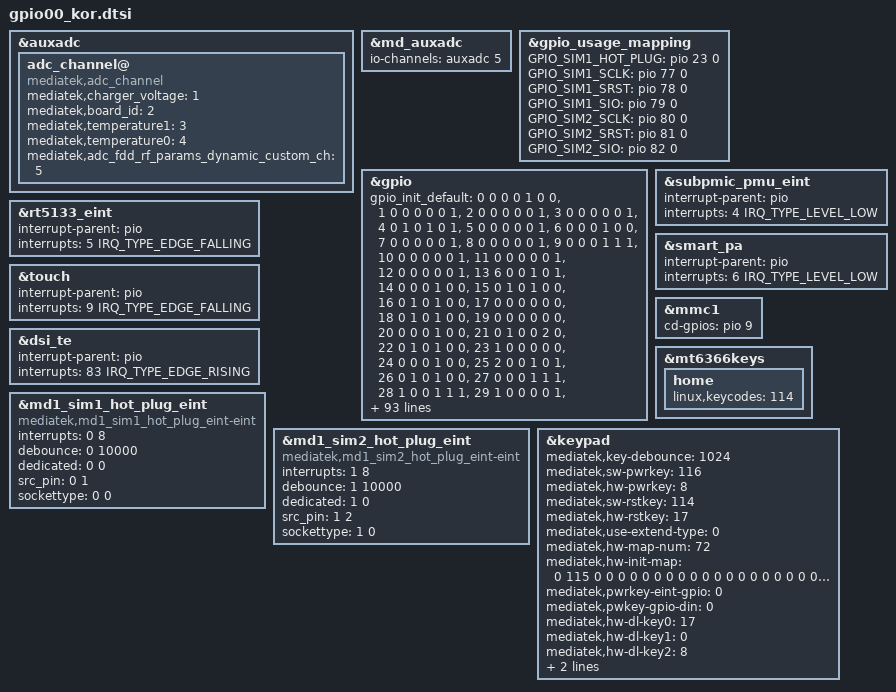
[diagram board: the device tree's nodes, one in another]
// SPDX-License-Identifier: (GPL-2.0 OR MIT)
/*
 * Copyright (C) 2022 MediaTek Inc.
 */
/*
 * Generated by MTK SP DrvGen Version: 3.5.160809 for MT6789.
 * 2022-03-30 15:44:54
 * Do Not Modify The File.
 * Copyright Mediatek Inc. (c) 2022.
 */

/*************************
 * ADC DTSI File
 *************************/
&auxadc {
	adc_channel@ {
		compatible = "mediatek,adc_channel";
		mediatek,charger_voltage = <1>;
		mediatek,board_id = <2>;
		mediatek,temperature1 = <3>;
		mediatek,temperature0 = <4>;
		mediatek,adc_fdd_rf_params_dynamic_custom_ch = <5>;
		status = "okay";
	};
};
&md_auxadc {
	io-channels = <&auxadc 5>;
};

/*************************
 * CLK_BUF DTSI File
 *************************/


#if 0
/*************************
 * I2C DTSI File
 *************************/
&pio {
	if_pmic_irq: if_pmic_irq {
		pins_cmd_dat {
			pinmux = <PINMUX_GPIO7__FUNC_GPIO7>;
			slew-rate = <1>;
			bias-disable;
			output-high;
		};
	};
	usbpd_irq: usbpd_irq {
		pins_cmd_dat {
			pinmux = <PINMUX_GPIO8__FUNC_GPIO8>;
			slew-rate = <1>;
			bias-disable;
			output-high;
		};
	};
};

&i2c0 {
	#address-cells = <1>;
	#size-cells = <0>;
	status = "okay";
	clock-frequency = <400000>;

	usbpd-sm5714@33 {
		status = "okay";
		compatible = "sm5714-usbpd";
		reg = <0x33>;
		pinctrl-names = "default";
		pinctrl-0 = <&usbpd_irq>;
		usbpd,usbpd_int = <&pio 8 0>;

		support_pd_role_swap;
		pdic-manager {
			/* sink */
			pdic,max_power = <5000>;
			pdic_op_power = <2500>;
			pdic_max_voltage = <6000>;
			pdic_max_current = <2000>;
			pdic,min_current = <500>;
			pdic,giveback = <0>;
			pdic,usb_com_capable = <1>;
			pdic,no_usb_suspend = <1>;

			/* source */
			source,max_voltage = <5000>;
			source,min_voltage = <4000>;
			source,max_power = <2500>;
		};
	};

	sm5714@49{
		status = "okay";
		compatible = "siliconmitus,sm5714mfd";
		reg = <0x49>;
		pinctrl-names = "default";
		pinctrl-0 = <&if_pmic_irq>;
		sm5714,irq-gpio = <&pio 7 0>;
		sm5714,wakeup;
	};
};
#endif

/*************************
 * GPIO DTSI File
 *************************/

&gpio_usage_mapping {
	GPIO_SIM1_HOT_PLUG = <&pio 23 0>;
	GPIO_SIM1_SCLK = <&pio 77 0>;
	GPIO_SIM1_SRST = <&pio 78 0>;
	GPIO_SIM1_SIO = <&pio 79 0>;
	GPIO_SIM2_SCLK = <&pio 80 0>;
	GPIO_SIM2_SRST = <&pio 81 0>;
	GPIO_SIM2_SIO = <&pio 82 0>;
};

&gpio{
	gpio_init_default = <0 0 0 0 1 0 0>,	/* FG_ERR */
		<1 0 0 0 0 0 1>,
		<2 0 0 0 0 0 1>,
		<3 0 0 0 0 0 1>,
		<4 0 1 0 1 0 1>,
		<5 0 0 0 0 0 1>,
		<6 0 0 0 1 0 0>,	/* OCTA_ESD_DET */
		<7 0 0 0 0 0 1>,
		<8 0 0 0 0 0 1>,
		<9 0 0 0 1 1 1>,
		<10 0 0 0 0 0 1>,
		<11 0 0 0 0 0 1>,
		<12 0 0 0 0 0 1>,
		<13 6 0 0 1 0 1>,
		<14 0 0 0 1 0 0>,	/* PCD_INT */
		<15 0 1 0 1 0 0>,
		<16 0 1 0 1 0 0>,
		<17 0 0 0 0 0 0>,
		<18 0 1 0 1 0 0>,
		<19 0 0 0 0 0 0>,
		<20 0 0 0 1 0 0>,
		<21 0 1 0 0 2 0>,	/* LCD_EN_3P0 */
		<22 0 1 0 1 0 0>,
		<23 1 0 0 0 0 0>,
		<24 0 0 0 1 0 0>,
		<25 2 0 0 1 0 1>,
		<26 0 1 0 1 0 0>,	/* RCAM3_LDO_EN */
		<27 0 0 0 1 1 1>,	/* BAT_ID_1 */
		<28 1 0 0 1 1 1>,
		<29 1 0 0 0 0 1>,
		<30 0 0 0 1 0 0>,	/* NC */
		<31 0 0 0 1 0 0>,	/* NC */
		<32 0 0 0 1 0 0>,	/* NC */
		<33 0 0 0 1 0 0>,	/* NC */
		<34 0 1 0 1 0 0>,
		<35 0 0 0 0 2 0>,	/* LCD_CON_DET */
		<36 0 0 0 0 0 0>,
		<37 0 0 0 0 0 0>,
		<38 2 0 0 0 0 1>,
		<39 2 0 0 0 0 1>,
		<40 2 0 0 0 0 1>,
		<41 2 0 0 1 0 1>,
		<42 0 1 0 0 0 0>,
		<43 0 1 0 0 0 0>,
		<44 0 1 0 0 0 0>,
		<45 0 1 0 1 0 0>,
		<46 6 0 0 1 0 0>,
		<47 6 0 0 1 0 0>,
		<48 6 0 0 0 0 0>,
		<49 6 0 0 1 0 0>,
		<50 2 0 0 0 0 1>,
		<51 2 0 0 0 0 1>,
		<52 2 0 0 0 0 1>,
		<53 2 0 0 1 0 1>,
		<54 0 0 0 1 0 0>,
		<55 0 0 0 1 0 0>,
		<56 0 0 0 1 0 0>,
		<57 0 0 0 1 0 0>,
		<58 0 0 0 1 0 0>,
		<59 0 0 0 1 0 0>,
		<60 0 0 0 1 0 0>,
		<61 0 0 0 1 0 0>,
		<62 0 0 0 1 0 0>,
		<63 0 0 0 1 0 0>,
		<64 0 0 0 1 0 0>,
		<65 0 0 0 1 0 0>,
		<66 1 0 0 1 1 0>,
		<67 1 0 0 1 1 1>,
		<68 5 0 0 0 0 1>,
		<69 0 0 0 1 0 1>,
		<77 1 0 0 0 0 1>,
		<78 1 0 0 0 0 1>,
		<79 1 0 0 1 1 1>,
		<80 1 0 0 0 0 1>,
		<81 1 0 0 0 0 1>,
		<82 1 0 0 1 1 1>,
		<83 1 0 0 1 0 1>,
		<84 0 1 0 1 0 1>,
		<85 0 1 0 0 2 0>,	/* OCTA_RST_N */
		<86 0 0 0 0 0 0>,
		<87 1 0 0 1 0 0>,
		<88 0 0 0 1 0 0>,	/* NC */
		<89 1 0 0 1 0 0>,
		<90 0 0 0 1 0 0>,	/* NC */
		<91 1 0 0 0 0 0>,	/* DIV_BAND_SEL0 */
		<92 1 0 0 0 0 0>,	/* DIV_BAND_SEL1 */
		<93 1 0 0 0 0 0>,	/* DIV_BAND_SEL2 */
		<94 1 0 0 0 0 0>,	/* DIV_BAND_SEL3 */
		<95 1 0 0 0 0 0>,	/* DIV_BAND_SEL4 */
		<96 0 0 0 1 0 0>,	/* NC */
		<97 1 0 0 0 0 0>,	/* DRX_B1_3_4_66_DCS_LNA_EN */
		<98 1 0 0 0 0 0>,	/* DRX_B5_8_26_GSM850_EGSM_LNA_EN */
		<99 1 0 0 0 0 0>,	/* DRX_B7_LNA_EN */
		<100 0 0 0 1 0 0>,	/* NC */
		<101 0 0 0 0 0 0>,
		<102 0 0 0 1 1 1>,
		<103 0 0 0 0 0 0>,
		<104 0 0 0 0 0 0>,
		<105 0 1 0 1 0 0>,  /* RCAM2_LDO_EN */
		<106 0 0 0 1 1 1>,	/* BAT_ID_2 */
		<107 0 1 0 1 0 0>,
		<108 0 0 0 0 2 0>,
		<109 0 0 0 0 0 0>,
		<110 0 0 0 0 0 0>,
		<111 0 0 0 1 0 0>,
		<112 1 0 0 0 0 0>,
		<113 1 0 0 1 0 0>,
		<114 1 0 0 0 0 0>,
		<115 1 0 0 1 0 0>,
		<116 1 0 0 0 0 0>,
		<117 1 0 0 1 0 0>,
		<118 1 0 0 0 0 0>,
		<119 1 0 0 1 0 0>,
		<120 1 0 0 0 0 0>,
		<121 1 0 0 1 0 0>,
		<122 1 0 0 0 0 0>,
		<123 1 0 0 0 0 0>,
		<124 1 0 0 1 0 0>,
		<125 1 0 0 1 0 0>,
		<126 1 0 0 1 0 0>,
		<127 1 0 0 1 0 0>,
		<128 1 0 0 1 0 0>,
		<129 1 0 0 1 0 0>,
		<130 1 0 0 1 1 1>,
		<131 1 0 0 1 1 1>,
		<132 2 0 0 0 0 0>,
		<133 2 0 0 0 0 0>,
		<134 1 0 0 1 1 1>,
		<135 1 0 0 1 1 1>,
		<136 1 0 0 0 0 1>,
		<137 1 0 0 0 0 1>,
		<138 1 0 0 1 1 1>,
		<139 1 0 0 1 1 1>,
		<140 1 0 0 1 1 1>,
		<141 1 0 0 1 1 1>,
		<142 1 0 0 1 1 1>,
		<143 1 0 0 1 1 1>,
		<144 1 0 0 1 1 1>,
		<145 1 0 0 1 1 1>,
		<146 1 0 0 1 1 1>,
		<147 1 0 0 1 1 1>,
		<148 1 0 0 1 1 1>,
		<149 1 0 0 1 1 1>,
		<150 0 1 0 1 0 1>,
		<151 0 1 0 1 0 1>,
		<152 0 1 0 0 2 0>,	/* LCD_EN_1P8 */
		<153 0 1 0 1 0 1>,
		<154 0 1 0 1 0 1>,
		<155 0 1 0 1 0 1>,
		<156 0 1 0 1 0 1>,
		<157 0 1 1 0 0 1>,
		<158 0 1 0 1 0 0>,
		<159 0 0 0 1 0 0>,
		<160 1 0 0 0 0 1>,
		<161 1 0 0 0 0 1>,
		<162 1 0 0 0 0 1>,
		<163 1 0 0 1 0 1>,
		<164 1 0 0 0 0 1>,
		<165 1 0 0 0 0 1>,
		<166 1 0 0 0 0 1>,
		<167 1 0 0 1 0 1>,
		<168 1 0 0 0 0 0>,
		<169 1 0 0 0 0 1>,
		<170 1 0 0 0 0 1>,
		<171 1 0 0 0 0 1>,
		<172 1 0 0 0 0 1>,
		<173 1 0 0 1 0 1>,
		<174 1 0 0 1 0 1>,
		<175 1 0 0 1 0 1>,
		<176 1 0 0 1 0 1>,
		<177 0 0 0 1 0 0>,
		<178 0 0 0 1 0 0>,
		<179 0 0 0 1 0 0>,
		<180 0 0 0 1 0 0>,
		<181 0 0 0 1 0 0>,
		<182 0 0 0 1 0 0>,
		<183 0 0 0 1 0 0>,
		<184 0 0 0 1 0 0>,
		<185 0 0 0 1 0 0>,
		<186 0 0 0 1 0 1>,
		<187 0 0 0 1 0 1>,
		<188 0 0 0 1 0 0>,
		<189 0 0 0 1 0 0>,
		<190 0 0 0 1 0 0>,
		<191 0 0 0 1 0 0>,
		<192 0 0 0 1 0 0>,
		<193 0 0 0 1 0 0>,
		<194 0 0 0 1 0 0>,
		<195 0 0 0 1 0 0>,
		<196 0 0 0 1 0 0>,
		<197 0 0 0 1 0 0>,
		<198 0 0 0 1 0 0>,
		<199 0 0 0 1 0 0>,
		<200 0 0 0 1 0 0>,
		<201 0 0 0 1 0 0>,
		<202 0 0 0 1 0 0>,
		<203 0 0 0 1 0 0>,
		<204 0 0 0 1 0 0>,
		<205 0 0 0 1 0 0>,
		<206 0 0 0 1 0 0>,
		<207 0 0 0 1 0 0>,
		<208 0 0 0 1 0 0>,
		<209 0 0 0 1 0 0>,
		<210 0 0 0 1 0 0>,
		<211 0 0 0 1 0 0>,
		<212 0 0 0 1 0 0>,
		<213 0 0 0 1 0 0>,
		<214 0 0 0 1 0 0>,
		<215 0 0 0 1 0 0>,
		<216 0 0 0 1 0 0>,
		<217 0 0 0 1 0 0>,
		<218 0 0 0 1 0 0>,
		<219 0 0 0 1 0 0>,
		<220 0 0 0 1 0 0>,
		<221 0 0 0 1 0 0>;
};


/*************************
 * EINT DTSI File
 *************************/

#include <dt-bindings/interrupt-controller/irq.h>
#include <dt-bindings/interrupt-controller/arm-gic.h>
#include <dt-bindings/gpio/gpio.h>

&subpmic_pmu_eint {
	interrupt-parent = <&pio>;
	interrupts = <4 IRQ_TYPE_LEVEL_LOW>;
	status = "okay";
};

&rt5133_eint {
	interrupt-parent = <&pio>;
	interrupts = <5 IRQ_TYPE_EDGE_FALLING>;
	status = "okay";
};

&smart_pa {
	interrupt-parent = <&pio>;
	interrupts = <6 IRQ_TYPE_LEVEL_LOW>;
	status = "okay";
};

&touch {
	interrupt-parent = <&pio>;
	interrupts = <9 IRQ_TYPE_EDGE_FALLING>;
	status = "okay";
};

&dsi_te {
	interrupt-parent = <&pio>;
	interrupts = <83 IRQ_TYPE_EDGE_RISING>;
	status = "okay";
};

&mmc1 {
	cd-gpios = <&pio 9 GPIO_ACTIVE_HIGH>;
};

/*************************
 * MD1_EINT DTSI File
 *************************/

&md1_sim1_hot_plug_eint {
	compatible = "mediatek,md1_sim1_hot_plug_eint-eint";
	interrupts = <0 8>;
	debounce = <0 10000>;
	dedicated = <0 0>;
	src_pin = <0 1>;
	sockettype = <0 0>;
	status = "okay";
};

&md1_sim2_hot_plug_eint {
	compatible = "mediatek,md1_sim2_hot_plug_eint-eint";
	interrupts = <1 8>;
	debounce = <1 10000>;
	dedicated = <1 0>;
	src_pin = <1 2>;
	sockettype = <1 0>;
	status = "okay";
};



/*************************
 * PMIC DTSI File
 *************************/



/*************************
 * POWER DTSI File
 *************************/



/*************************
 * KPD DTSI File
 *************************/

&mt6366keys {
	home {
		linux,keycodes = <114>;
	};
};

&keypad {
	mediatek,key-debounce = <1024>;
	mediatek,sw-pwrkey = <116>;
	mediatek,hw-pwrkey = <8>;
	mediatek,sw-rstkey  = <114>;
	mediatek,hw-rstkey = <17>;
	mediatek,use-extend-type = <0>;
	/*HW Keycode [0~71] -> Linux Keycode*/
	mediatek,hw-map-num = <72>;
	mediatek,hw-init-map = <0 115 0 0 0 0 0 0 0 0 0 0 0 0 0 0 0 0 0 0
	0 0 0 0 0 0 0 0 0 0 0 0 0 0 0 0 0 0 0 0 0 0 0 0 0 0 0 0 0 0 0 0 0 0 0
	0 0 0 0 0 0 0 0 0 0 0 0 0 0 0 0 0 >;
	mediatek,pwrkey-eint-gpio = <0>;
	mediatek,pwkey-gpio-din  = <0>;
	mediatek,hw-dl-key0 = <17>;
	mediatek,hw-dl-key1 = <0>;
	mediatek,hw-dl-key2 = <8>;
	mediatek,hw-recovery-key = <17>;
	mediatek,hw-factory-key = <0>;
	status = "okay";
};


